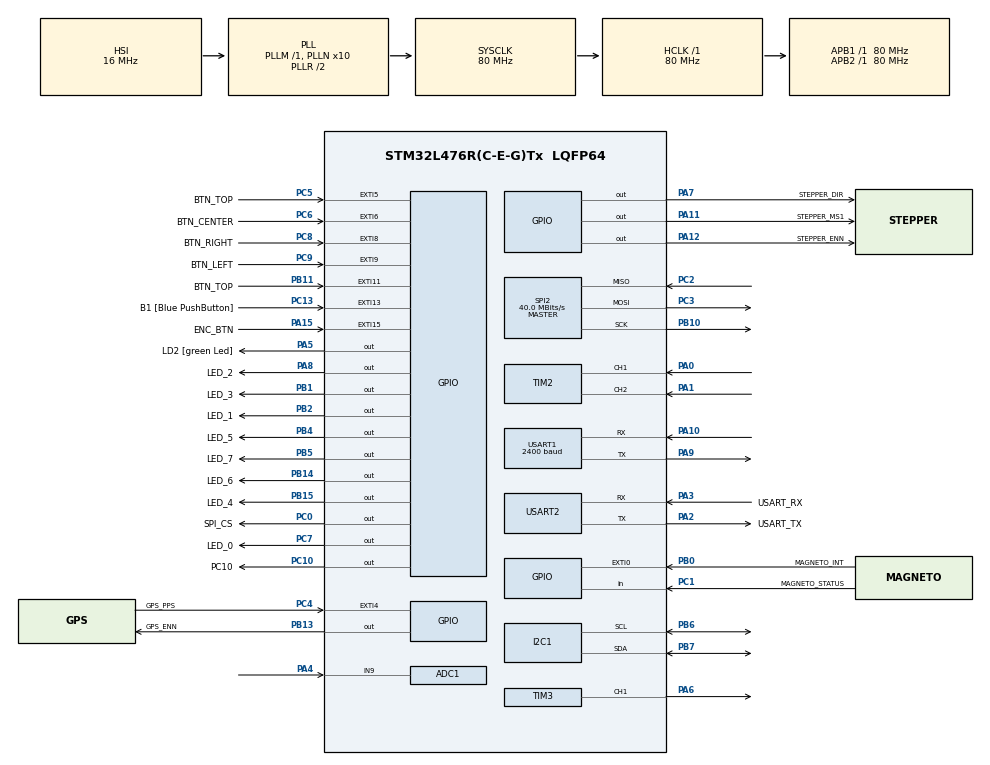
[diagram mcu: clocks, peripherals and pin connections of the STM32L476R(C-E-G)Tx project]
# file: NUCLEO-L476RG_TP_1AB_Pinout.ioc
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ADC1.Channel-2\#ChannelRegularConversion=ADC_CHANNEL_9
ADC1.NbrOfConversionFlag=1
ADC1.OffsetNumber-2\#ChannelRegularConversion=ADC_OFFSET_NONE
ADC1.Rank-2\#ChannelRegularConversion=1
ADC1.SamplingTime-2\#ChannelRegularConversion=ADC_SAMPLETIME_2CYCLES_5
ADC1.master=1
I2C1.Timing=0x10909CEC
Mcu.Family=STM32L4
Mcu.Name=STM32L476R(C-E-G)Tx
Mcu.Package=LQFP64
NVIC.PriorityGroup=NVIC_PRIORITYGROUP_4
NVIC.TIM6_DAC_IRQn=true\:15\:0\:false\:false\:true\:false\:true\:true
NVIC.TimeBase=TIM6_DAC_IRQn
NVIC.TimeBaseIP=TIM6
PA0.Signal=S_TIM2_CH1
PA1.Signal=S_TIM2_CH2
PA10.Mode=Asynchronous
PA10.Signal=USART1_RX
PA11.GPIO_Label=STEPPER_MS1
PA11.Signal=GPIO_Output
PA12.GPIO_Label=STEPPER_ENN
PA12.Signal=GPIO_Output
PA13\ (JTMS-SWDIO).GPIO_Label=TMS
PA13\ (JTMS-SWDIO).Mode=Trace_Asynchronous_SW
PA13\ (JTMS-SWDIO).Signal=SYS_JTMS-SWDIO
PA14\ (JTCK-SWCLK).GPIO_Label=TCK
PA14\ (JTCK-SWCLK).Mode=Trace_Asynchronous_SW
PA14\ (JTCK-SWCLK).Signal=SYS_JTCK-SWCLK
PA15\ (JTDI).GPIO_Label=ENC_BTN
PA15\ (JTDI).Signal=GPXTI15
PA2.GPIO_Label=USART_TX
PA2.GPIO_Mode=GPIO_MODE_AF_PP
PA2.GPIO_PuPd=GPIO_NOPULL
PA2.GPIO_Speed=GPIO_SPEED_FREQ_VERY_HIGH
PA2.Mode=Asynchronous
PA2.Signal=USART2_TX
PA3.GPIO_Label=USART_RX
PA3.GPIO_Mode=GPIO_MODE_AF_PP
PA3.GPIO_PuPd=GPIO_NOPULL
PA3.GPIO_Speed=GPIO_SPEED_FREQ_VERY_HIGH
PA3.Mode=Asynchronous
PA3.Signal=USART2_RX
PA4.Signal=ADCx_IN9
PA5.GPIO_Label=LD2 [green Led]
PA5.GPIO_ModeDefaultOutputPP=GPIO_MODE_OUTPUT_PP
PA5.GPIO_PuPd=GPIO_NOPULL
PA5.GPIO_Speed=GPIO_SPEED_FREQ_LOW
PA5.Signal=GPIO_Output
PA6.Signal=S_TIM3_CH1
PA7.GPIO_Label=STEPPER_DIR
PA7.Signal=GPIO_Output
PA8.GPIO_Label=LED_2
PA8.Signal=GPIO_Output
PA9.Mode=Asynchronous
PA9.Signal=USART1_TX
PB0.GPIO_Label=MAGNETO_INT
PB0.Signal=GPXTI0
PB1.GPIO_Label=LED_3
PB1.Signal=GPIO_Output
PB10.Mode=Full_Duplex_Master
PB10.Signal=SPI2_SCK
PB11.GPIO_Label=BTN_TOP
PB11.Signal=GPXTI11
PB13.GPIO_Label=GPS_ENN
PB13.Signal=GPIO_Output
PB14.GPIO_Label=LED_6
PB14.Signal=GPIO_Output
PB15.GPIO_Label=LED_4
PB15.Signal=GPIO_Output
PB2.GPIO_Label=LED_1
PB2.Signal=GPIO_Output
PB3\ (JTDO-TRACESWO).Mode=Trace_Asynchronous_SW
PB3\ (JTDO-TRACESWO).Signal=SYS_JTDO-SWO
PB4\ (NJTRST).GPIO_Label=LED_5
PB4\ (NJTRST).Signal=GPIO_Output
PB5.GPIO_Label=LED_7
PB5.Signal=GPIO_Output
PB6.Mode=I2C
PB6.Signal=I2C1_SCL
PB7.Mode=I2C
PB7.Signal=I2C1_SDA
PC0.GPIO_Label=SPI_CS
PC0.Signal=GPIO_Output
PC1.GPIO_Label=MAGNETO_STATUS
PC1.Signal=GPIO_Input
PC10.GPIO_Label=PC10
PC10.Signal=GPIO_Output
PC13.GPIO_Label=B1 [Blue PushButton]
PC13.GPIO_ModeDefaultEXTI=GPIO_MODE_IT_FALLING
PC13.GPIO_PuPd=GPIO_NOPULL
PC13.Signal=GPXTI13
PC14-OSC32_IN\ (PC14).Mode=LSE-External-Oscillator
PC14-OSC32_IN\ (PC14).Signal=RCC_OSC32_IN
PC15-OSC32_OUT\ (PC15).Mode=LSE-External-Oscillator
PC15-OSC32_OUT\ (PC15).Signal=RCC_OSC32_OUT
PC2.Mode=Full_Duplex_Master
PC2.Signal=SPI2_MISO
PC3.Mode=Full_Duplex_Master
PC3.Signal=SPI2_MOSI
PC4.GPIO_Label=GPS_PPS
PC4.Signal=GPXTI4
PC5.GPIO_Label=BTN_TOP
PC5.Signal=GPXTI5
PC6.GPIO_Label=BTN_CENTER
PC6.Signal=GPXTI6
PC7.GPIO_Label=LED_0
PC7.Signal=GPIO_Output
PC8.GPIO_Label=BTN_RIGHT
PC8.Signal=GPXTI8
PC9.GPIO_Label=BTN_LEFT
PC9.Signal=GPXTI9
PH0-OSC_IN\ (PH0).Mode=HSE-External-Oscillator
PH0-OSC_IN\ (PH0).Signal=RCC_OSC_IN
PH1-OSC_OUT\ (PH1).Mode=HSE-External-Oscillator
PH1-OSC_OUT\ (PH1).Signal=RCC_OSC_OUT
ProjectManager.HeapSize=0x200
ProjectManager.StackSize=0x400
ProjectManager.TargetToolchain=STM32CubeIDE
RCC.ADCFreq_Value=64000000
RCC.AHBFreq_Value=80000000
RCC.APB1Freq_Value=80000000
RCC.APB1TimFreq_Value=80000000
RCC.APB2Freq_Value=80000000
RCC.APB2TimFreq_Value=80000000
RCC.CortexFreq_Value=80000000
RCC.HCLKFreq_Value=80000000
RCC.HSE_VALUE=8000000
RCC.HSI_VALUE=16000000
RCC.MSI_VALUE=4000000
RCC.PLLN=10
RCC.PLLSourceVirtual=RCC_PLLSOURCE_HSI
RCC.PREFETCH_ENABLE=1
RCC.SYSCLKFreq_VALUE=80000000
RCC.SYSCLKSource=RCC_SYSCLKSOURCE_PLLCLK
RCC.USBFreq_Value=64000000
RCC.VCOOutputFreq_Value=160000000
SH.ADCx_IN9.0=ADC1_IN9,IN9-Single-Ended
SH.S_TIM2_CH1.0=TIM2_CH1,Encoder_Interface
SH.S_TIM2_CH2.0=TIM2_CH2,Encoder_Interface
SH.S_TIM3_CH1.0=TIM3_CH1,PWM Generation1 CH1
SPI2.CalculateBaudRate=40.0 MBits/s
SPI2.Direction=SPI_DIRECTION_2LINES
SPI2.Mode=SPI_MODE_MASTER
SPI2.VirtualType=VM_MASTER
TIM3.Channel-PWM\ Generation1\ CH1=TIM_CHANNEL_1
USART1.BaudRate=2400
USART1.VirtualMode-Asynchronous=VM_ASYNC
USART2.VirtualMode-Asynchronous=VM_ASYNC
VP_SYS_VS_tim6.Mode=TIM6
VP_TIM3_VS_ClockSourceINT.Mode=Internal
board=NUCLEO-L476RG

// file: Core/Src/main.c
/* USER CODE BEGIN Header */
/**
  ******************************************************************************
  * @file           : main.c
  * @brief          : Main program body
  ******************************************************************************
  * @attention
  *
  * Copyright (c) 2024 STMicroelectronics.
  * All rights reserved.
  *
  * This software is licensed under terms that can be found in the LICENSE file
  * in the root directory of this software component.
  * If no LICENSE file comes with this software, it is provided AS-IS.
  *
  ******************************************************************************
  */
/* USER CODE END Header */
#include "main.h"
#include "adc.h"
#include "i2c.h"
#include "spi.h"
#include "tim.h"
#include "usart.h"
#include "gpio.h"

void SystemClock_Config(void);

int main(void)
{

  /* MCU Configuration--------------------------------------------------------*/

  /* Reset of all peripherals, Initializes the Flash interface and the Systick. */
  HAL_Init();

  /* Configure the system clock */
  SystemClock_Config();

  /* Initialize all configured peripherals */
  MX_GPIO_Init();
  MX_USART2_UART_Init();
  MX_I2C1_Init();
  MX_SPI2_Init();
  MX_TIM2_Init();
  MX_TIM3_Init();
  MX_USART1_UART_Init();
  MX_ADC1_Init();

  /* Infinite loop */
  /* USER CODE BEGIN WHILE */
  while (1)
  {
	  uint8_t delay;
	  HAL_GPIO_TogglePin(PC10_GPIO_Port, PC10_Pin);
	  HAL_Delay(30);
	  delay = (delay > 50) ? 10 : delay+1;
    /* USER CODE END WHILE */

  }
}

void SystemClock_Config(void)
{
  RCC_OscInitTypeDef RCC_OscInitStruct = {0};
  RCC_ClkInitTypeDef RCC_ClkInitStruct = {0};

  /** Configure the main internal regulator output voltage
  */
  if (HAL_PWREx_ControlVoltageScaling(PWR_REGULATOR_VOLTAGE_SCALE1) != HAL_OK)
  {
    Error_Handler();
  }

  /** Initializes the RCC Oscillators according to the specified parameters
  * in the RCC_OscInitTypeDef structure.
  */
  RCC_OscInitStruct.OscillatorType = RCC_OSCILLATORTYPE_HSI;
  RCC_OscInitStruct.HSIState = RCC_HSI_ON;
  RCC_OscInitStruct.HSICalibrationValue = RCC_HSICALIBRATION_DEFAULT;
  RCC_OscInitStruct.PLL.PLLState = RCC_PLL_ON;
  RCC_OscInitStruct.PLL.PLLSource = RCC_PLLSOURCE_HSI;
  RCC_OscInitStruct.PLL.PLLM = 1;
  RCC_OscInitStruct.PLL.PLLN = 10;
  RCC_OscInitStruct.PLL.PLLP = RCC_PLLP_DIV7;
  RCC_OscInitStruct.PLL.PLLQ = RCC_PLLQ_DIV2;
  RCC_OscInitStruct.PLL.PLLR = RCC_PLLR_DIV2;
  if (HAL_RCC_OscConfig(&RCC_OscInitStruct) != HAL_OK)
  {
    Error_Handler();
  }

  /** Initializes the CPU, AHB and APB buses clocks
  */
  RCC_ClkInitStruct.ClockType = RCC_CLOCKTYPE_HCLK|RCC_CLOCKTYPE_SYSCLK
                              |RCC_CLOCKTYPE_PCLK1|RCC_CLOCKTYPE_PCLK2;
  RCC_ClkInitStruct.SYSCLKSource = RCC_SYSCLKSOURCE_PLLCLK;
  RCC_ClkInitStruct.AHBCLKDivider = RCC_SYSCLK_DIV1;
  RCC_ClkInitStruct.APB1CLKDivider = RCC_HCLK_DIV1;
  RCC_ClkInitStruct.APB2CLKDivider = RCC_HCLK_DIV1;

  if (HAL_RCC_ClockConfig(&RCC_ClkInitStruct, FLASH_LATENCY_4) != HAL_OK)
  {
    Error_Handler();
  }
}

void HAL_TIM_PeriodElapsedCallback(TIM_HandleTypeDef *htim)
{
  if (htim->Instance == TIM6) {
    HAL_IncTick();
  }
}

void Error_Handler(void)
{
  __disable_irq();
  while (1)
  {
  }
}
